# MK51DZ10 register map
Vendor: Freescale Semiconductor, Inc.; Series: Kinetis_K; File version: 1.6
CPU: CM4 r0p1, little endian, no MPU, no FPU, VTOR, 4 interrupt priority bits
Registers are 32-bit, read-write, reset 0x0 unless marked. A register's access mark holds for its fields unless they carry their own. Offsets are from the block's base; [hi:lo] are bit positions; {n}, {i} and the like mark numbered series; 'fields as' and 'values as' point back to an identical list.

## TRIAMP0 — Trans-Impedance Amplifier
Base 0x400F8000; register names take the prefix TRIAMP0_
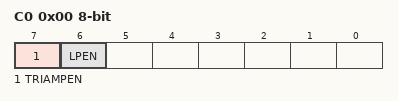
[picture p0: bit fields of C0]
0x00 C0 8-bit — Control Register 0
  [7] TRIAMPEN — TRIAMP Enable
    0=The amplifier is disabled and not powered; 1=TRIAMP system is enabled. In this mode the amplifier is powered and enabled.
  [6] LPEN — Low-Power Enable
    0=High-speed mode selected. In this mode, TRIAMP has faster slew rate and unity gain bandwidth performance with higher current consumption.; 1=Low-power mode selected. In this mode, TRIAMP has lower current consumption with slower slew rate and unity gain bandwidth performance.

## TRIAMP1 — Trans-Impedance Amplifier
Base 0x400F8800; register names take the prefix TRIAMP1_
Registers as TRIAMP0.

## PTA — General Purpose Input/Output
Base 0x400FF000; register names take the prefix GPIOA_
0x00 PDOR — Port Data Output Register
  [31:0] PDO — Port Data Output
    0=Logic level 0 is driven on pin provided pin is configured for General Purpose Output; 1=Logic level 1 is driven on pin provided pin is configured for General Purpose Output
0x04 PSOR wo — Port Set Output Register
  [31:0] PTSO — Port Set Output
    0=Corresponding bit in PDORn does not change; 1=Corresponding bit in PDORn is set to logic one
0x08 PCOR wo — Port Clear Output Register
  [31:0] PTCO — Port Clear Output
    0=Corresponding bit in PDORn does not change; 1=Corresponding bit in PDORn is set to logic zero
0x0C PTOR wo — Port Toggle Output Register
  [31:0] PTTO — Port Toggle Output
    0=Corresponding bit in PDORn does not change; 1=Corresponding bit in PDORn is set to the inverse of its existing logic state
0x10 PDIR ro — Port Data Input Register
  [31:0] PDI — Port Data Input
    0=Pin logic level is logic zero or is configured for use by digital function; 1=Pin logic level is logic one
0x14 PDDR — Port Data Direction Register
  [31:0] PDD — Port data direction
    0=Pin is configured as general purpose input, if configured for the GPIO function; 1=Pin is configured for general purpose output, if configured for the GPIO function

## PTB — General Purpose Input/Output
Base 0x400FF040; register names take the prefix GPIOB_
Registers as PTA.

## PTC — General Purpose Input/Output
Base 0x400FF080; register names take the prefix GPIOC_
Registers as PTA; these are added or differ:
0x08 PCOR wo — Port Clear Output Register
  [31:0] PTCO — Port Clear Output
    0=Corresponding bit in PDORn does not change; 1=Corresponding bit in PDORn is set to logic zero

## PTD — General Purpose Input/Output
Base 0x400FF0C0; register names take the prefix GPIOD_
Registers as PTA.

## PTE — General Purpose Input/Output
Base 0x400FF100; register names take the prefix GPIOE_
Registers as PTA.

## SysTick — System timer
Base 0xE000E010; register names take the prefix SYST_
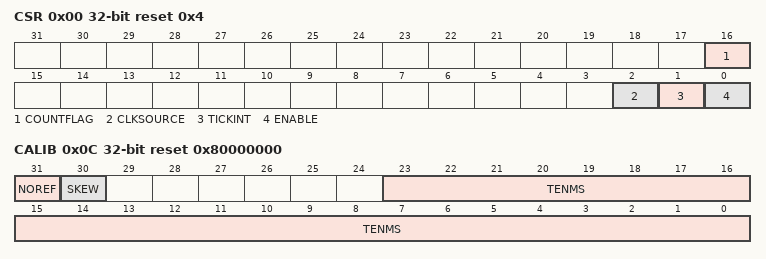
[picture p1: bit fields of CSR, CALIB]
0x00 CSR reset 0x4 — SysTick Control and Status Register
  [16] COUNTFLAG
  [2] CLKSOURCE
    0=external clock; 1=processor clock
  [1] TICKINT
    0=counting down to 0 does not assert the SysTick exception request; 1=counting down to 0 asserts the SysTick exception request
  [0] ENABLE
    0=counter disabled; 1=counter enabled
0x04 RVR — SysTick Reload Value Register
  [23:0] RELOAD — Value to load into the SysTick Current Value Register when the counter reaches 0
0x08 CVR — SysTick Current Value Register
  [23:0] CURRENT — Current value at the time the register is accessed
0x0C CALIB ro reset 0x80000000 — SysTick Calibration Value Register
  [31] NOREF
    0=The reference clock is provided; 1=The reference clock is not provided
  [30] SKEW
    0=10ms calibration value is exact; 1=10ms calibration value is inexact, because of the clock frequency
  [23:0] TENMS — Reload value to use for 10ms timing

## NVIC — Nested Vectored Interrupt Controller
Base 0xE000E100
{0x0+4i} NVICISER{i} (i=0..3) — Interrupt Set Enable Register n
  [31:0] SETENA — Interrupt set enable bits
{0x80+4i} NVICICER{i} (i=0..3) — Interrupt Clear Enable Register n
  [31:0] CLRENA — Interrupt clear-enable bits
{0x100+4i} NVICISPR{i} (i=0..3) — Interrupt Set Pending Register n
  [31:0] SETPEND — Interrupt set-pending bits
{0x180+4i} NVICICPR{i} (i=0..3) — Interrupt Clear Pending Register n
  [31:0] CLRPEND — Interrupt clear-pending bits
{0x200+4i} NVICIABR{i} (i=0..3) — Interrupt Active bit Register n
  [31:0] ACTIVE — Interrupt active flags
{0x300+i} NVICIP{i} 8-bit (i=0..105) — Interrupt Priority Register n
  [7:0] PRI{i} — Priority of interrupt {i}
0xE00 NVICSTIR — Software Trigger Interrupt Register
  [8:0] INTID — Interrupt ID of the interrupt to trigger, in the range 0-239. For example, a value of 0x03 specifies interrupt IRQ3.

## MCM — Core Platform Miscellaneous Control Module
Base 0xE0080000; register names take the prefix MCM_
0x08 PLASC 16-bit ro reset 0x1F — Crossbar switch (AXBS) slave configuration
  [7:0] ASC — Each bit in the ASC field indicates if there is a corresponding connection to the crossbar switch's slave input port.
    0=A bus slave connection to AXBS input port n is absent; 1=A bus slave connection to AXBS input port n is present
0x0A PLAMC 16-bit ro reset 0x3F — Crossbar switch (AXBS) master configuration
  [7:0] AMC — Each bit in the AMC field indicates if there is a corresponding connection to the AXBS master input port.
    0=A bus master connection to AXBS input port n is absent; 1=A bus master connection to AXBS input port n is present
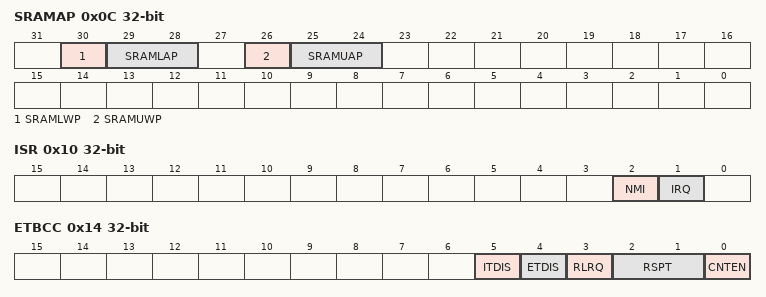
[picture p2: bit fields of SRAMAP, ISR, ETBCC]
0x0C SRAMAP — SRAM arbitration and protection
  [30] SRAMLWP — SRAM_L write protect
  [29:28] SRAMLAP — SRAM_L arbitration priority
    0=Round robin; 1=Special round robin (favors SRAM backoor accesses over the processor); 2=Fixed priority. Processor has highest, backdoor has lowest; 3=Fixed priority. Backdoor has highest, processor has lowest
  [26] SRAMUWP — SRAM_U write protect
  [25:24] SRAMUAP — SRAM_U arbitration priority
    values as SRAMLAP
0x10 ISR — Interrupt status register
  [2] NMI — Non-maskable interrupt pending
    0=No pending NMI; 1=Due to the ETB counter expiring, an NMI is pending
  [1] IRQ — Normal interrupt pending
    0=No pending interrupt; 1=Due to the ETB counter expiring, a normal interrupt is pending
0x14 ETBCC — ETB counter control register
  [5] ITDIS — ITM-to-TPIU disable
    0=ITM-to-TPIU trace path enabled; 1=ITM-to-TPIU trace path disabled
  [4] ETDIS — ETM-to-TPIU disable
    0=ETM-to-TPIU trace path enabled; 1=ETM-to-TPIU trace path disabled
  [3] RLRQ — Reload request
    0=No effect; 1=Clears pending debug halt, NMI, or IRQ interrupt requests
  [2:1] RSPT — Response type
    0=No response when the ETB count expires; 1=Generate a normal interrupt when the ETB count expires; 2=Generate an NMI when the ETB count expires; 3=Generate a debug halt when the ETB count expires
  [0] CNTEN — Counter enable
    0=ETB counter disabled; 1=ETB counter enabled
0x18 ETBRL — ETB reload register
  [10:0] RELOAD — Byte count reload value
0x1C ETBCNT ro — ETB counter value register
  [10:0] COUNTER — Byte count counter value

## Notices in the file
Redistribution and use in source and binary forms, with or without modification,
are permitted provided that the following conditions are met:
o Redistributions of source code must retain the above copyright notice, this list
of conditions and the following disclaimer.
o Redistributions in binary form must reproduce the above copyright notice, this
list of conditions and the following disclaimer in the documentation and/or
other materials provided with the distribution.
o Neither the name of Freescale Semiconductor, Inc. nor the names of its
contributors may be used to endorse or promote products derived from this
software without specific prior written permission.
THIS SOFTWARE IS PROVIDED BY THE COPYRIGHT HOLDERS AND CONTRIBUTORS "AS IS" AND
ANY EXPRESS OR IMPLIED WARRANTIES, INCLUDING, BUT NOT LIMITED TO, THE IMPLIED
WARRANTIES OF MERCHANTABILITY AND FITNESS FOR A PARTICULAR PURPOSE ARE
DISCLAIMED. IN NO EVENT SHALL THE COPYRIGHT HOLDER OR CONTRIBUTORS BE LIABLE FOR
ANY DIRECT, INDIRECT, INCIDENTAL, SPECIAL, EXEMPLARY, OR CONSEQUENTIAL DAMAGES
(INCLUDING, BUT NOT LIMITED TO, PROCUREMENT OF SUBSTITUTE GOODS OR SERVICES;
LOSS OF USE, DATA, OR PROFITS; OR BUSINESS INTERRUPTION) HOWEVER CAUSED AND ON
ANY THEORY OF LIABILITY, WHETHER IN CONTRACT, STRICT LIABILITY, OR TORT
(INCLUDING NEGLIGENCE OR OTHERWISE) ARISING IN ANY WAY OUT OF THE USE OF THIS
SOFTWARE, EVEN IF ADVISED OF THE POSSIBILITY OF SUCH DAMAGE.
